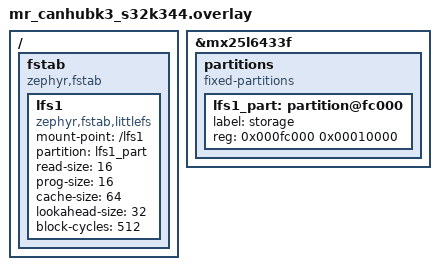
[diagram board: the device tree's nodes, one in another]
/*
 * Copyright 2023 NXP
 *
 * SPDX-License-Identifier: Apache-2.0
 */

/delete-node/ &storage_partition;

/ {
	fstab {
		compatible = "zephyr,fstab";
		lfs1: lfs1 {
			compatible = "zephyr,fstab,littlefs";
			mount-point = "/lfs1";
			partition = <&lfs1_part>;
			read-size = <16>;
			prog-size = <16>;
			cache-size = <64>;
			lookahead-size = <32>;
			block-cycles = <512>;
		};
	};
};

&mx25l6433f {
	partitions {
		compatible = "fixed-partitions";
		#address-cells = <1>;
		#size-cells = <1>;
		lfs1_part: partition@fc000 {
			label = "storage";
			reg = <0x000fc000 0x00010000>;
		};
	};
};
